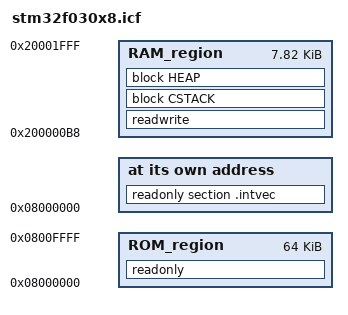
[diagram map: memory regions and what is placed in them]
/*###ICF### Section handled by ICF editor, don't touch! ****/
/*-Editor annotation file-*/
/* IcfEditorFile="$TOOLKIT_DIR$\config\ide\IcfEditor\cortex_v1_0.xml" */
/*-Specials-*/
define symbol __ICFEDIT_intvec_start__ = 0x08000000;
/*-Memory Regions-*/
define symbol __ICFEDIT_region_ROM_start__ = 0x08000000;
define symbol __ICFEDIT_region_ROM_end__   = 0x0800FFFF;
/* [RAM = 8kb = 0x2000] Vector table dynamic copy: 45 vectors = 180 bytes (0xB4) to be reserved in RAM */
define symbol __ICFEDIT_region_RAM_start__ = 0x200000B8; /* Add 4 more bytes after NVIC section to be aligned on 8 bytes */
define symbol __ICFEDIT_region_RAM_end__   = 0x20001FFF;
/*-Sizes-*/
if (!isdefinedsymbol(MBED_BOOT_STACK_SIZE)) {
    define symbol MBED_BOOT_STACK_SIZE = 0x400;
}
define symbol __ICFEDIT_size_cstack__ = MBED_BOOT_STACK_SIZE;
define symbol __ICFEDIT_size_heap__   = 0x800;
/**** End of ICF editor section. ###ICF###*/

define memory mem with size = 4G;
define region ROM_region   = mem:[from __ICFEDIT_region_ROM_start__   to __ICFEDIT_region_ROM_end__];
define region RAM_region   = mem:[from __ICFEDIT_region_RAM_start__   to __ICFEDIT_region_RAM_end__];

define block CSTACK    with alignment = 8, size = __ICFEDIT_size_cstack__   { };
define block HEAP      with alignment = 8, size = __ICFEDIT_size_heap__     { };

initialize by copy { readwrite };
do not initialize  { section .noinit };

place at address mem:__ICFEDIT_intvec_start__ { readonly section .intvec };

place in ROM_region   { readonly };
place in RAM_region   { readwrite,
                        block CSTACK, block HEAP };

export symbol __ICFEDIT_region_RAM_start__;
export symbol __ICFEDIT_region_RAM_end__;
